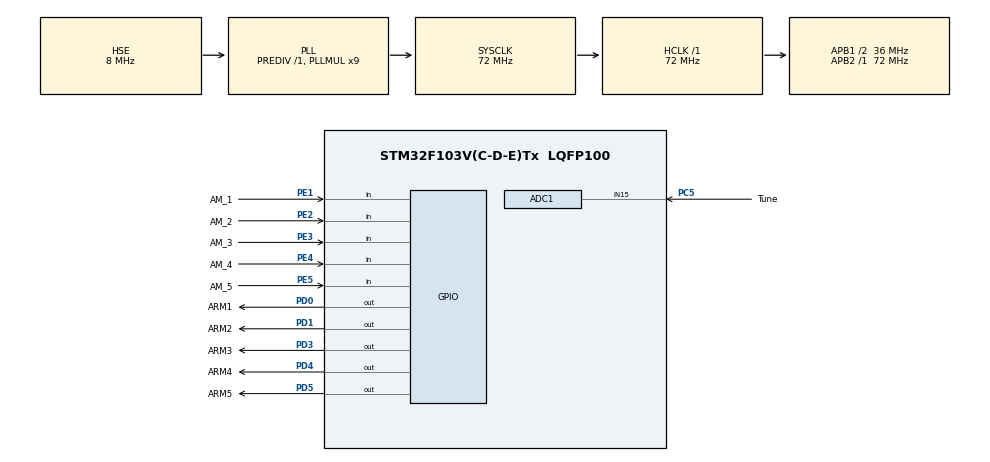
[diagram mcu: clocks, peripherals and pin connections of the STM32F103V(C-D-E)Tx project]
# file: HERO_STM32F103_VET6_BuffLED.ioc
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ADC1.Channel-0\#ChannelRegularConversion=ADC_CHANNEL_15
ADC1.NbrOfConversionFlag=1
ADC1.Rank-0\#ChannelRegularConversion=1
ADC1.SamplingTime-0\#ChannelRegularConversion=ADC_SAMPLETIME_1CYCLE_5
ADC1.master=1
Dma.Request0=TIM1_UP
Dma.TIM1_UP.0.Direction=DMA_MEMORY_TO_PERIPH
Dma.TIM1_UP.0.Instance=DMA1_Channel5
Dma.TIM1_UP.0.MemDataAlignment=DMA_MDATAALIGN_BYTE
Dma.TIM1_UP.0.MemInc=DMA_MINC_ENABLE
Dma.TIM1_UP.0.Mode=DMA_CIRCULAR
Dma.TIM1_UP.0.PeriphDataAlignment=DMA_PDATAALIGN_HALFWORD
Dma.TIM1_UP.0.PeriphInc=DMA_PINC_DISABLE
Dma.TIM1_UP.0.Priority=DMA_PRIORITY_HIGH
Mcu.Family=STM32F1
Mcu.Name=STM32F103V(C-D-E)Tx
Mcu.Package=LQFP100
NVIC.DMA1_Channel5_IRQn=true\:0\:0\:false\:false\:true\:false\:true
NVIC.PriorityGroup=NVIC_PRIORITYGROUP_4
NVIC.TIM6_IRQn=true\:0\:0\:false\:false\:true\:true\:true
OSC_IN.Mode=HSE-External-Oscillator
OSC_IN.Signal=RCC_OSC_IN
OSC_OUT.Mode=HSE-External-Oscillator
OSC_OUT.Signal=RCC_OSC_OUT
PA13.Mode=Serial_Wire
PA13.Signal=SYS_JTMS-SWDIO
PA14.Mode=Serial_Wire
PA14.Signal=SYS_JTCK-SWCLK
PC5.GPIO_Label=Tune
PC5.Signal=ADCx_IN15
PD0.GPIO_Label=ARM1
PD0.GPIO_Speed=GPIO_SPEED_FREQ_HIGH
PD0.PinState=GPIO_PIN_RESET
PD0.Signal=GPIO_Output
PD1.GPIO_Label=ARM2
PD1.GPIO_Speed=GPIO_SPEED_FREQ_HIGH
PD1.PinState=GPIO_PIN_RESET
PD1.Signal=GPIO_Output
PD3.GPIO_Label=ARM3
PD3.GPIO_Speed=GPIO_SPEED_FREQ_HIGH
PD3.PinState=GPIO_PIN_RESET
PD3.Signal=GPIO_Output
PD4.GPIO_Label=ARM4
PD4.GPIO_Speed=GPIO_SPEED_FREQ_HIGH
PD4.Signal=GPIO_Output
PD5.GPIO_Label=ARM5
PD5.GPIO_Speed=GPIO_SPEED_FREQ_HIGH
PD5.Signal=GPIO_Output
PE1.GPIO_Label=AM_1
PE1.GPIO_PuPd=GPIO_PULLDOWN
PE1.Signal=GPIO_Input
PE2.GPIO_Label=AM_2
PE2.GPIO_PuPd=GPIO_PULLDOWN
PE2.Signal=GPIO_Input
PE3.GPIO_Label=AM_3
PE3.GPIO_PuPd=GPIO_PULLDOWN
PE3.Signal=GPIO_Input
PE4.GPIO_Label=AM_4
PE4.GPIO_PuPd=GPIO_PULLDOWN
PE4.Signal=GPIO_Input
PE5.GPIO_Label=AM_5
PE5.GPIO_PuPd=GPIO_PULLDOWN
PE5.Signal=GPIO_Input
ProjectManager.HeapSize=0x200
ProjectManager.StackSize=0x400
ProjectManager.TargetToolchain=EWARM V8
RCC.ADCPresc=RCC_ADCPCLK2_DIV6
RCC.AHBFreq_Value=72000000
RCC.APB1CLKDivider=RCC_HCLK_DIV2
RCC.APB1Freq_Value=36000000
RCC.APB1TimFreq_Value=72000000
RCC.APB2Freq_Value=72000000
RCC.APB2TimFreq_Value=72000000
RCC.HCLKFreq_Value=72000000
RCC.PLLMUL=RCC_PLL_MUL9
RCC.PLLSourceVirtual=RCC_PLLSOURCE_HSE
RCC.SYSCLKFreq_VALUE=72000000
RCC.SYSCLKSource=RCC_SYSCLKSOURCE_PLLCLK
RCC.USBFreq_Value=72000000
SH.ADCx_IN15.0=ADC1_IN15,IN15
TIM1.AutoReloadPreload=TIM_AUTORELOAD_PRELOAD_ENABLE
TIM1.Period=26
TIM1.TIM_MasterOutputTrigger=TIM_TRGO_UPDATE
TIM6.AutoReloadPreload=TIM_AUTORELOAD_PRELOAD_ENABLE
TIM6.Period=1000
TIM6.Prescaler=71
VP_TIM1_VS_ClockSourceINT.Mode=Internal
VP_TIM6_VS_ClockSourceINT.Mode=Enable_Timer
board=custom

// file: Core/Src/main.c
/* USER CODE BEGIN Header */
/**
  ******************************************************************************
  * @file           : main.c
  * @brief          : Main program body
  ******************************************************************************
  * @attention
  *
  * <h2><center>&copy; Copyright (c) 2021 STMicroelectronics.
  * All rights reserved.</center></h2>
  *
  * This software component is licensed by ST under BSD 3-Clause license,
  * the "License"; You may not use this file except in compliance with the
  * License. You may obtain a copy of the License at:
  *                        opensource.org/licenses/BSD-3-Clause
  *
  ******************************************************************************
  */
/* USER CODE END Header */
#include "main.h"

/* USER CODE BEGIN Includes */
#include "mod_Arm.h"
#include "drv_pix.h"
/* USER CODE END Includes */

ADC_HandleTypeDef hadc1;

TIM_HandleTypeDef htim1;
TIM_HandleTypeDef htim6;
DMA_HandleTypeDef hdma_tim1_up;

void SystemClock_Config(void);
static void MX_GPIO_Init(void);
static void MX_DMA_Init(void);
static void MX_TIM1_Init(void);
static void MX_ADC1_Init(void);
static void MX_TIM6_Init(void);

int main(void)
{
  /* USER CODE BEGIN 1 */
  int fori;
  /* USER CODE END 1 */

  /* MCU Configuration--------------------------------------------------------*/

  /* Reset of all peripherals, Initializes the Flash interface and the Systick. */
  HAL_Init();

  /* Configure the system clock */
  SystemClock_Config();

  /* Initialize all configured peripherals */
  MX_GPIO_Init();
  MX_DMA_Init();
  MX_TIM1_Init();
  MX_ADC1_Init();
  MX_TIM6_Init();
  /* USER CODE BEGIN 2 */
  Data_Init(); // 初始化发送数组
  ARMData_Load(); // 初始化扇叶数据

  HAL_Delay(200); // 上电延时，避免误触发和灯条异常

  HAL_TIM_DMA_Send_Start(); // 启动循环全速发送

  HAL_TIM_Base_Start_IT(&htim6); // 启动1ms轮询

  /* USER CODE END 2 */

  /* Infinite loop */
  /* USER CODE BEGIN WHILE */
  while (1)
  {
    for (fori = 0; fori < 5; fori++)
    {
      // 显示函数仅修改内存，被其它中断打断运行过程不会导致显示错误
      // 显示函数仅在扇叶状态发生变化时对需要变化的区域对应的内存进行修改
      ARMGen(&ARMs[fori]); // 轮询刷新显示
    }

    /* USER CODE END WHILE */

  }
}

void SystemClock_Config(void)
{
  RCC_OscInitTypeDef RCC_OscInitStruct = {0};
  RCC_ClkInitTypeDef RCC_ClkInitStruct = {0};
  RCC_PeriphCLKInitTypeDef PeriphClkInit = {0};

  /** Initializes the RCC Oscillators according to the specified parameters
  * in the RCC_OscInitTypeDef structure.
  */
  RCC_OscInitStruct.OscillatorType = RCC_OSCILLATORTYPE_HSE;
  RCC_OscInitStruct.HSEState = RCC_HSE_ON;
  RCC_OscInitStruct.HSEPredivValue = RCC_HSE_PREDIV_DIV1;
  RCC_OscInitStruct.HSIState = RCC_HSI_ON;
  RCC_OscInitStruct.PLL.PLLState = RCC_PLL_ON;
  RCC_OscInitStruct.PLL.PLLSource = RCC_PLLSOURCE_HSE;
  RCC_OscInitStruct.PLL.PLLMUL = RCC_PLL_MUL9;
  if (HAL_RCC_OscConfig(&RCC_OscInitStruct) != HAL_OK)
  {
    Error_Handler();
  }
  /** Initializes the CPU, AHB and APB buses clocks
  */
  RCC_ClkInitStruct.ClockType = RCC_CLOCKTYPE_HCLK|RCC_CLOCKTYPE_SYSCLK
                              |RCC_CLOCKTYPE_PCLK1|RCC_CLOCKTYPE_PCLK2;
  RCC_ClkInitStruct.SYSCLKSource = RCC_SYSCLKSOURCE_PLLCLK;
  RCC_ClkInitStruct.AHBCLKDivider = RCC_SYSCLK_DIV1;
  RCC_ClkInitStruct.APB1CLKDivider = RCC_HCLK_DIV2;
  RCC_ClkInitStruct.APB2CLKDivider = RCC_HCLK_DIV1;

  if (HAL_RCC_ClockConfig(&RCC_ClkInitStruct, FLASH_LATENCY_2) != HAL_OK)
  {
    Error_Handler();
  }
  PeriphClkInit.PeriphClockSelection = RCC_PERIPHCLK_ADC;
  PeriphClkInit.AdcClockSelection = RCC_ADCPCLK2_DIV6;
  if (HAL_RCCEx_PeriphCLKConfig(&PeriphClkInit) != HAL_OK)
  {
    Error_Handler();
  }
}

static void MX_ADC1_Init(void)
{

  ADC_ChannelConfTypeDef sConfig = {0};

  /** Common config
  */
  hadc1.Instance = ADC1;
  hadc1.Init.ScanConvMode = ADC_SCAN_DISABLE;
  hadc1.Init.ContinuousConvMode = DISABLE;
  hadc1.Init.DiscontinuousConvMode = DISABLE;
  hadc1.Init.ExternalTrigConv = ADC_SOFTWARE_START;
  hadc1.Init.DataAlign = ADC_DATAALIGN_RIGHT;
  hadc1.Init.NbrOfConversion = 1;
  if (HAL_ADC_Init(&hadc1) != HAL_OK)
  {
    Error_Handler();
  }
  /** Configure Regular Channel
  */
  sConfig.Channel = ADC_CHANNEL_15;
  sConfig.Rank = ADC_REGULAR_RANK_1;
  sConfig.SamplingTime = ADC_SAMPLETIME_1CYCLE_5;
  if (HAL_ADC_ConfigChannel(&hadc1, &sConfig) != HAL_OK)
  {
    Error_Handler();
  }

}

static void MX_TIM1_Init(void)
{

  TIM_ClockConfigTypeDef sClockSourceConfig = {0};
  TIM_MasterConfigTypeDef sMasterConfig = {0};

  htim1.Instance = TIM1;
  htim1.Init.Prescaler = 0;
  htim1.Init.CounterMode = TIM_COUNTERMODE_UP;
  htim1.Init.Period = 26;
  htim1.Init.ClockDivision = TIM_CLOCKDIVISION_DIV1;
  htim1.Init.RepetitionCounter = 0;
  htim1.Init.AutoReloadPreload = TIM_AUTORELOAD_PRELOAD_ENABLE;
  if (HAL_TIM_Base_Init(&htim1) != HAL_OK)
  {
    Error_Handler();
  }
  sClockSourceConfig.ClockSource = TIM_CLOCKSOURCE_INTERNAL;
  if (HAL_TIM_ConfigClockSource(&htim1, &sClockSourceConfig) != HAL_OK)
  {
    Error_Handler();
  }
  sMasterConfig.MasterOutputTrigger = TIM_TRGO_UPDATE;
  sMasterConfig.MasterSlaveMode = TIM_MASTERSLAVEMODE_DISABLE;
  if (HAL_TIMEx_MasterConfigSynchronization(&htim1, &sMasterConfig) != HAL_OK)
  {
    Error_Handler();
  }

}

static void MX_TIM6_Init(void)
{

  TIM_MasterConfigTypeDef sMasterConfig = {0};

  htim6.Instance = TIM6;
  htim6.Init.Prescaler = 71;
  htim6.Init.CounterMode = TIM_COUNTERMODE_UP;
  htim6.Init.Period = 1000;
  htim6.Init.AutoReloadPreload = TIM_AUTORELOAD_PRELOAD_ENABLE;
  if (HAL_TIM_Base_Init(&htim6) != HAL_OK)
  {
    Error_Handler();
  }
  sMasterConfig.MasterOutputTrigger = TIM_TRGO_RESET;
  sMasterConfig.MasterSlaveMode = TIM_MASTERSLAVEMODE_DISABLE;
  if (HAL_TIMEx_MasterConfigSynchronization(&htim6, &sMasterConfig) != HAL_OK)
  {
    Error_Handler();
  }

}

static void MX_DMA_Init(void)
{

  /* DMA controller clock enable */
  __HAL_RCC_DMA1_CLK_ENABLE();

  /* DMA interrupt init */
  /* DMA1_Channel5_IRQn interrupt configuration */
  HAL_NVIC_SetPriority(DMA1_Channel5_IRQn, 0, 0);
  HAL_NVIC_EnableIRQ(DMA1_Channel5_IRQn);

}

static void MX_GPIO_Init(void)
{
  GPIO_InitTypeDef GPIO_InitStruct = {0};

  /* GPIO Ports Clock Enable */
  __HAL_RCC_GPIOE_CLK_ENABLE();
  __HAL_RCC_GPIOC_CLK_ENABLE();
  __HAL_RCC_GPIOA_CLK_ENABLE();
  __HAL_RCC_GPIOD_CLK_ENABLE();

  /*Configure GPIO pin Output Level */
  HAL_GPIO_WritePin(GPIOD, ARM1_Pin|ARM2_Pin|ARM3_Pin|ARM4_Pin
                          |ARM5_Pin, GPIO_PIN_RESET);

  /*Configure GPIO pins : AM_2_Pin AM_3_Pin AM_4_Pin AM_5_Pin
                           AM_1_Pin */
  GPIO_InitStruct.Pin = AM_2_Pin|AM_3_Pin|AM_4_Pin|AM_5_Pin
                          |AM_1_Pin;
  GPIO_InitStruct.Mode = GPIO_MODE_INPUT;
  GPIO_InitStruct.Pull = GPIO_PULLDOWN;
  HAL_GPIO_Init(GPIOE, &GPIO_InitStruct);

  /*Configure GPIO pins : ARM1_Pin ARM2_Pin ARM3_Pin ARM4_Pin
                           ARM5_Pin */
  GPIO_InitStruct.Pin = ARM1_Pin|ARM2_Pin|ARM3_Pin|ARM4_Pin
                          |ARM5_Pin;
  GPIO_InitStruct.Mode = GPIO_MODE_OUTPUT_PP;
  GPIO_InitStruct.Pull = GPIO_NOPULL;
  GPIO_InitStruct.Speed = GPIO_SPEED_FREQ_HIGH;
  HAL_GPIO_Init(GPIOD, &GPIO_InitStruct);

}

void Error_Handler(void)
{
  __disable_irq();
  while (1)
  {
  }
}

/************************ (C) COPYRIGHT STMicroelectronics *****END OF FILE****/
